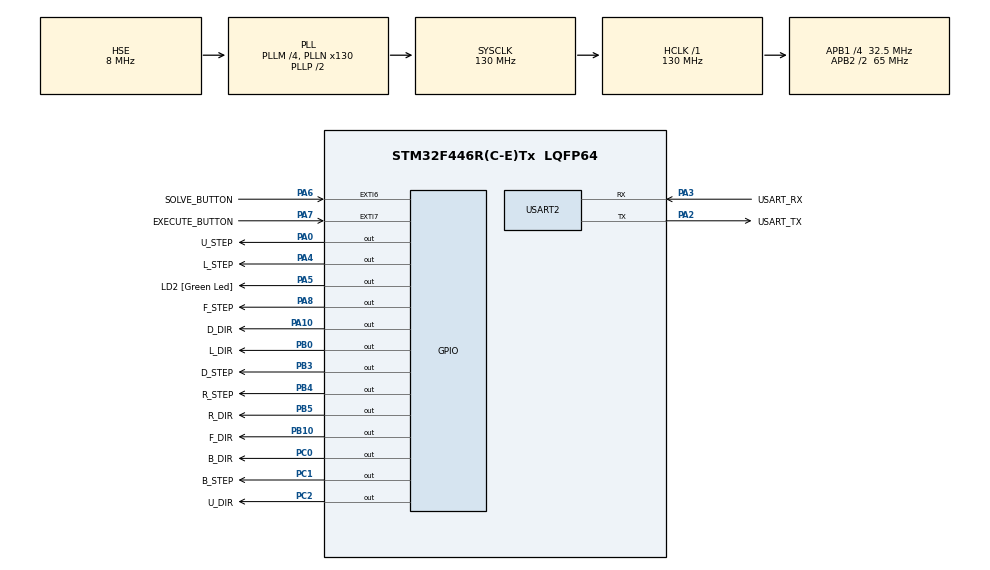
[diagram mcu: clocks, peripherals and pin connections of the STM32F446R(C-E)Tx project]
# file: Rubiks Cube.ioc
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FREERTOS.Tasks01=CubeProcessTask,24,4096,CubeProcessStart,As weak,NULL,Dynamic,NULL,NULL
FREERTOS.configTOTAL_HEAP_SIZE=32768
Mcu.Family=STM32F4
Mcu.Name=STM32F446R(C-E)Tx
Mcu.Package=LQFP64
NVIC.EXTI9_5_IRQn=true\:5\:0\:false\:false\:true\:true\:true\:true\:true
NVIC.PriorityGroup=NVIC_PRIORITYGROUP_4
NVIC.TIM1_UP_TIM10_IRQn=true\:0\:0\:false\:false\:true\:false\:false\:true\:true
NVIC.TIM3_IRQn=true\:5\:0\:false\:false\:true\:true\:true\:true\:true
NVIC.TimeBase=TIM1_UP_TIM10_IRQn
NVIC.TimeBaseIP=TIM10
NVIC.USART2_IRQn=true\:5\:0\:false\:false\:true\:true\:true\:true\:true
PA0-WKUP.GPIO_Label=U_STEP
PA0-WKUP.Signal=GPIO_Output
PA10.GPIO_Label=D_DIR
PA10.Signal=GPIO_Output
PA13.GPIO_Label=TMS
PA13.Mode=Serial_Wire
PA13.Signal=SYS_JTMS-SWDIO
PA14.GPIO_Label=TCK
PA14.Mode=Serial_Wire
PA14.Signal=SYS_JTCK-SWCLK
PA2.GPIO_Label=USART_TX
PA2.Mode=Asynchronous
PA2.Signal=USART2_TX
PA3.GPIO_Label=USART_RX
PA3.Mode=Asynchronous
PA3.Signal=USART2_RX
PA4.GPIO_Label=L_STEP
PA4.Signal=GPIO_Output
PA5.GPIO_Label=LD2 [Green Led]
PA5.Signal=GPIO_Output
PA6.GPIO_Label=SOLVE_BUTTON
PA6.Signal=GPXTI6
PA7.GPIO_Label=EXECUTE_BUTTON
PA7.Signal=GPXTI7
PA8.GPIO_Label=F_STEP
PA8.Signal=GPIO_Output
PB0.GPIO_Label=L_DIR
PB0.Signal=GPIO_Output
PB10.GPIO_Label=F_DIR
PB10.Signal=GPIO_Output
PB3.GPIO_Label=D_STEP
PB3.Signal=GPIO_Output
PB4.GPIO_Label=R_STEP
PB4.Signal=GPIO_Output
PB5.GPIO_Label=R_DIR
PB5.Signal=GPIO_Output
PC0.GPIO_Label=B_DIR
PC0.Signal=GPIO_Output
PC1.GPIO_Label=B_STEP
PC1.Signal=GPIO_Output
PC14-OSC32_IN.Signal=RCC_OSC32_IN
PC15-OSC32_OUT.Signal=RCC_OSC32_OUT
PC2.GPIO_Label=U_DIR
PC2.Signal=GPIO_Output
PH0-OSC_IN.Mode=HSE-External-Oscillator
PH0-OSC_IN.Signal=RCC_OSC_IN
PH1-OSC_OUT.Mode=HSE-External-Oscillator
PH1-OSC_OUT.Signal=RCC_OSC_OUT
ProjectManager.HeapSize=0x200
ProjectManager.StackSize=0x400
ProjectManager.TargetToolchain=STM32CubeIDE
RCC.48MHZClocksFreq_Value=84000000
RCC.AHBFreq_Value=130000000
RCC.APB1CLKDivider=RCC_HCLK_DIV4
RCC.APB1Freq_Value=32500000
RCC.APB1TimFreq_Value=65000000
RCC.APB2CLKDivider=RCC_HCLK_DIV2
RCC.APB2Freq_Value=65000000
RCC.APB2TimFreq_Value=130000000
RCC.CortexFreq_Value=130000000
RCC.FLatency-AdvancedSettings=FLASH_LATENCY_4
RCC.HCLKFreq_Value=130000000
RCC.HSE_VALUE=8000000
RCC.HSI_VALUE=16000000
RCC.PLLM=4
RCC.PLLN=130
RCC.PLLSourceVirtual=RCC_PLLSOURCE_HSE
RCC.SYSCLKFreq_VALUE=130000000
RCC.SYSCLKSource=RCC_SYSCLKSOURCE_PLLCLK
RCC.USBFreq_Value=130000000
RCC.VCOOutputFreq_Value=260000000
TIM3.Period=49
TIM3.Prescaler=75
USART2.VirtualMode=VM_ASYNC
VP_FREERTOS_VS_CMSIS_V2.Mode=CMSIS_V2
VP_SYS_VS_tim10.Mode=TIM10
VP_TIM3_VS_ClockSourceINT.Mode=Internal
board=NUCLEO-F446RE

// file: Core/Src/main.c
/* USER CODE BEGIN Header */
/**
  ******************************************************************************
  * @file           : main.c
  * @brief          : Main program body
  ******************************************************************************
  * @attention
  *
  * Copyright (c) 2026 STMicroelectronics.
  * All rights reserved.
  *
  * This software is licensed under terms that can be found in the LICENSE file
  * in the root directory of this software component.
  * If no LICENSE file comes with this software, it is provided AS-IS.
  *
  ******************************************************************************
  */
/* USER CODE END Header */
#include "main.h"
#include "cmsis_os.h"

TIM_HandleTypeDef htim3;

UART_HandleTypeDef huart2;

/* Definitions for CubeProcessTask */
osThreadId_t CubeProcessTaskHandle;
const osThreadAttr_t CubeProcessTask_attributes = {
  .name = "CubeProcessTask",
  .stack_size = 4096 * 4,
  .priority = (osPriority_t) osPriorityNormal,
};

void SystemClock_Config(void);
static void MX_GPIO_Init(void);
static void MX_USART2_UART_Init(void);
static void MX_TIM3_Init(void);
void CubeProcessStart(void *argument);

int main(void)
{

  /* MCU Configuration--------------------------------------------------------*/

  /* Reset of all peripherals, Initializes the Flash interface and the Systick. */
  HAL_Init();

  /* Configure the system clock */
  SystemClock_Config();

  /* Initialize all configured peripherals */
  MX_GPIO_Init();
  MX_USART2_UART_Init();
  MX_TIM3_Init();

  /* Init scheduler */
  osKernelInitialize();

  /* Create the thread(s) */
  /* creation of CubeProcessTask */
  CubeProcessTaskHandle = osThreadNew(CubeProcessStart, NULL, &CubeProcessTask_attributes);

  /* Start scheduler */
  osKernelStart();

  /* We should never get here as control is now taken by the scheduler */

  /* Infinite loop */
  while (1)
  {

  }
}

void SystemClock_Config(void)
{
  RCC_OscInitTypeDef RCC_OscInitStruct = {0};
  RCC_ClkInitTypeDef RCC_ClkInitStruct = {0};

  /** Configure the main internal regulator output voltage
  */
  __HAL_RCC_PWR_CLK_ENABLE();
  __HAL_PWR_VOLTAGESCALING_CONFIG(PWR_REGULATOR_VOLTAGE_SCALE2);

  /** Initializes the RCC Oscillators according to the specified parameters
  * in the RCC_OscInitTypeDef structure.
  */
  RCC_OscInitStruct.OscillatorType = RCC_OSCILLATORTYPE_HSE;
  RCC_OscInitStruct.HSEState = RCC_HSE_ON;
  RCC_OscInitStruct.PLL.PLLState = RCC_PLL_ON;
  RCC_OscInitStruct.PLL.PLLSource = RCC_PLLSOURCE_HSE;
  RCC_OscInitStruct.PLL.PLLM = 4;
  RCC_OscInitStruct.PLL.PLLN = 130;
  RCC_OscInitStruct.PLL.PLLP = RCC_PLLP_DIV2;
  RCC_OscInitStruct.PLL.PLLQ = 2;
  RCC_OscInitStruct.PLL.PLLR = 2;
  if (HAL_RCC_OscConfig(&RCC_OscInitStruct) != HAL_OK)
  {
    Error_Handler();
  }

  /** Initializes the CPU, AHB and APB buses clocks
  */
  RCC_ClkInitStruct.ClockType = RCC_CLOCKTYPE_HCLK|RCC_CLOCKTYPE_SYSCLK
                              |RCC_CLOCKTYPE_PCLK1|RCC_CLOCKTYPE_PCLK2;
  RCC_ClkInitStruct.SYSCLKSource = RCC_SYSCLKSOURCE_PLLCLK;
  RCC_ClkInitStruct.AHBCLKDivider = RCC_SYSCLK_DIV1;
  RCC_ClkInitStruct.APB1CLKDivider = RCC_HCLK_DIV4;
  RCC_ClkInitStruct.APB2CLKDivider = RCC_HCLK_DIV2;

  if (HAL_RCC_ClockConfig(&RCC_ClkInitStruct, FLASH_LATENCY_4) != HAL_OK)
  {
    Error_Handler();
  }
}

static void MX_TIM3_Init(void)
{

  TIM_ClockConfigTypeDef sClockSourceConfig = {0};
  TIM_MasterConfigTypeDef sMasterConfig = {0};

  htim3.Instance = TIM3;
  htim3.Init.Prescaler = 75;
  htim3.Init.CounterMode = TIM_COUNTERMODE_UP;
  htim3.Init.Period = 49;
  htim3.Init.ClockDivision = TIM_CLOCKDIVISION_DIV1;
  htim3.Init.AutoReloadPreload = TIM_AUTORELOAD_PRELOAD_DISABLE;
  if (HAL_TIM_Base_Init(&htim3) != HAL_OK)
  {
    Error_Handler();
  }
  sClockSourceConfig.ClockSource = TIM_CLOCKSOURCE_INTERNAL;
  if (HAL_TIM_ConfigClockSource(&htim3, &sClockSourceConfig) != HAL_OK)
  {
    Error_Handler();
  }
  sMasterConfig.MasterOutputTrigger = TIM_TRGO_RESET;
  sMasterConfig.MasterSlaveMode = TIM_MASTERSLAVEMODE_DISABLE;
  if (HAL_TIMEx_MasterConfigSynchronization(&htim3, &sMasterConfig) != HAL_OK)
  {
    Error_Handler();
  }

}

static void MX_USART2_UART_Init(void)
{

  huart2.Instance = USART2;
  huart2.Init.BaudRate = 115200;
  huart2.Init.WordLength = UART_WORDLENGTH_8B;
  huart2.Init.StopBits = UART_STOPBITS_1;
  huart2.Init.Parity = UART_PARITY_NONE;
  huart2.Init.Mode = UART_MODE_TX_RX;
  huart2.Init.HwFlowCtl = UART_HWCONTROL_NONE;
  huart2.Init.OverSampling = UART_OVERSAMPLING_16;
  if (HAL_UART_Init(&huart2) != HAL_OK)
  {
    Error_Handler();
  }

}

static void MX_GPIO_Init(void)
{
  GPIO_InitTypeDef GPIO_InitStruct = {0};

  /* GPIO Ports Clock Enable */
  __HAL_RCC_GPIOC_CLK_ENABLE();
  __HAL_RCC_GPIOH_CLK_ENABLE();
  __HAL_RCC_GPIOA_CLK_ENABLE();
  __HAL_RCC_GPIOB_CLK_ENABLE();

  /*Configure GPIO pin Output Level */
  HAL_GPIO_WritePin(GPIOC, B_DIR_Pin|B_STEP_Pin|U_DIR_Pin, GPIO_PIN_RESET);

  /*Configure GPIO pin Output Level */
  HAL_GPIO_WritePin(GPIOA, U_STEP_Pin|L_STEP_Pin|LD2_Pin|F_STEP_Pin
                          |D_DIR_Pin, GPIO_PIN_RESET);

  /*Configure GPIO pin Output Level */
  HAL_GPIO_WritePin(GPIOB, L_DIR_Pin|F_DIR_Pin|D_STEP_Pin|R_STEP_Pin
                          |R_DIR_Pin, GPIO_PIN_RESET);

  /*Configure GPIO pins : B_DIR_Pin B_STEP_Pin U_DIR_Pin */
  GPIO_InitStruct.Pin = B_DIR_Pin|B_STEP_Pin|U_DIR_Pin;
  GPIO_InitStruct.Mode = GPIO_MODE_OUTPUT_PP;
  GPIO_InitStruct.Pull = GPIO_NOPULL;
  GPIO_InitStruct.Speed = GPIO_SPEED_FREQ_LOW;
  HAL_GPIO_Init(GPIOC, &GPIO_InitStruct);

  /*Configure GPIO pins : U_STEP_Pin L_STEP_Pin LD2_Pin F_STEP_Pin
                           D_DIR_Pin */
  GPIO_InitStruct.Pin = U_STEP_Pin|L_STEP_Pin|LD2_Pin|F_STEP_Pin
                          |D_DIR_Pin;
  GPIO_InitStruct.Mode = GPIO_MODE_OUTPUT_PP;
  GPIO_InitStruct.Pull = GPIO_NOPULL;
  GPIO_InitStruct.Speed = GPIO_SPEED_FREQ_LOW;
  HAL_GPIO_Init(GPIOA, &GPIO_InitStruct);

  /*Configure GPIO pins : SOLVE_BUTTON_Pin EXECUTE_BUTTON_Pin */
  GPIO_InitStruct.Pin = SOLVE_BUTTON_Pin|EXECUTE_BUTTON_Pin;
  GPIO_InitStruct.Mode = GPIO_MODE_IT_RISING;
  GPIO_InitStruct.Pull = GPIO_NOPULL;
  HAL_GPIO_Init(GPIOA, &GPIO_InitStruct);

  /*Configure GPIO pins : L_DIR_Pin F_DIR_Pin D_STEP_Pin R_STEP_Pin
                           R_DIR_Pin */
  GPIO_InitStruct.Pin = L_DIR_Pin|F_DIR_Pin|D_STEP_Pin|R_STEP_Pin
                          |R_DIR_Pin;
  GPIO_InitStruct.Mode = GPIO_MODE_OUTPUT_PP;
  GPIO_InitStruct.Pull = GPIO_NOPULL;
  GPIO_InitStruct.Speed = GPIO_SPEED_FREQ_LOW;
  HAL_GPIO_Init(GPIOB, &GPIO_InitStruct);

  /* EXTI interrupt init*/
  HAL_NVIC_SetPriority(EXTI9_5_IRQn, 5, 0);
  HAL_NVIC_EnableIRQ(EXTI9_5_IRQn);

}

__weak void CubeProcessStart(void *argument)
{
  /* USER CODE BEGIN 5 */

  /* Infinite loop */
  for(;;)
  {
	osDelay(50);
  }
  /* USER CODE END 5 */
}

void HAL_TIM_PeriodElapsedCallback(TIM_HandleTypeDef *htim)
{
  if (htim->Instance == TIM10)
  {
    HAL_IncTick();
  }
}

void Error_Handler(void)
{
  __disable_irq();
  while (1)
  {
  }
}
